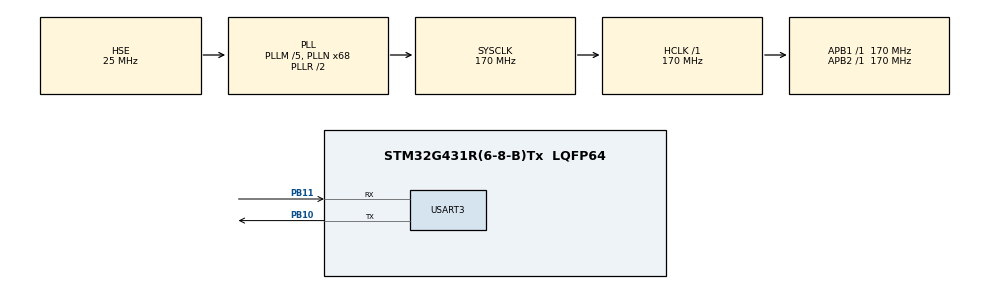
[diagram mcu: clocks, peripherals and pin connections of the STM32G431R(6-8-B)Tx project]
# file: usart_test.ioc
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Dma.Request0=USART3_TX
Dma.USART3_TX.0.Direction=DMA_MEMORY_TO_PERIPH
Dma.USART3_TX.0.EventEnable=DISABLE
Dma.USART3_TX.0.Instance=DMA1_Channel1
Dma.USART3_TX.0.MemDataAlignment=DMA_MDATAALIGN_BYTE
Dma.USART3_TX.0.MemInc=DMA_MINC_ENABLE
Dma.USART3_TX.0.Mode=DMA_CIRCULAR
Dma.USART3_TX.0.PeriphDataAlignment=DMA_PDATAALIGN_BYTE
Dma.USART3_TX.0.PeriphInc=DMA_PINC_DISABLE
Dma.USART3_TX.0.Polarity=HAL_DMAMUX_REQ_GEN_RISING
Dma.USART3_TX.0.Priority=DMA_PRIORITY_LOW
Dma.USART3_TX.0.RequestNumber=1
Dma.USART3_TX.0.SignalID=NONE
Dma.USART3_TX.0.SyncEnable=DISABLE
Dma.USART3_TX.0.SyncPolarity=HAL_DMAMUX_SYNC_NO_EVENT
Dma.USART3_TX.0.SyncRequestNumber=1
Dma.USART3_TX.0.SyncSignalID=NONE
Mcu.Family=STM32G4
Mcu.Name=STM32G431R(6-8-B)Tx
Mcu.Package=LQFP64
NVIC.DMA1_Channel1_IRQn=true\:0\:0\:false\:false\:true\:false\:true\:true
NVIC.PriorityGroup=NVIC_PRIORITYGROUP_4
PA13.Mode=Serial_Wire
PA13.Signal=SYS_JTMS-SWDIO
PA14.Mode=Serial_Wire
PA14.Signal=SYS_JTCK-SWCLK
PB10.Mode=Asynchronous
PB10.Signal=USART3_TX
PB11.Mode=Asynchronous
PB11.Signal=USART3_RX
PF0-OSC_IN.Mode=HSE-External-Oscillator
PF0-OSC_IN.Signal=RCC_OSC_IN
PF1-OSC_OUT.Mode=HSE-External-Oscillator
PF1-OSC_OUT.Signal=RCC_OSC_OUT
ProjectManager.HeapSize=0x200
ProjectManager.StackSize=0x400
ProjectManager.TargetToolchain=MDK-ARM V5.32
RCC.ADC12Freq_Value=170000000
RCC.AHBFreq_Value=170000000
RCC.APB1Freq_Value=170000000
RCC.APB1TimFreq_Value=170000000
RCC.APB2Freq_Value=170000000
RCC.APB2TimFreq_Value=170000000
RCC.CortexFreq_Value=170000000
RCC.EXTERNAL_CLOCK_VALUE=12288000
RCC.HCLKFreq_Value=170000000
RCC.HSE_VALUE=25000000
RCC.HSI48_VALUE=48000000
RCC.HSI_VALUE=16000000
RCC.LSE_VALUE=32768
RCC.PLLM=RCC_PLLM_DIV5
RCC.PLLN=68
RCC.PLLSourceVirtual=RCC_PLLSOURCE_HSE
RCC.SYSCLKFreq_VALUE=170000000
RCC.SYSCLKSource=RCC_SYSCLKSOURCE_PLLCLK
RCC.USBFreq_Value=170000000
RCC.VCOOutputFreq_Value=340000000
USART3.VirtualMode-Asynchronous=VM_ASYNC
VP_SYS_VS_DBSignals.Mode=DisableDeadBatterySignals
board=custom

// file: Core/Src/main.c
/* USER CODE BEGIN Header */
/**
  ******************************************************************************
  * @file           : main.c
  * @brief          : Main program body
  ******************************************************************************
  * @attention
  *
  * Copyright (c) 2023 STMicroelectronics.
  * All rights reserved.
  *
  * This software is licensed under terms that can be found in the LICENSE file
  * in the root directory of this software component.
  * If no LICENSE file comes with this software, it is provided AS-IS.
  *
  ******************************************************************************
  */
/* USER CODE END Header */
#include "main.h"
#include "dma.h"
#include "usart.h"
#include "gpio.h"

/* USER CODE BEGIN Includes */
#include "math.h"
/* USER CODE END Includes */

void SystemClock_Config(void);

/* USER CODE BEGIN 0 */
uint8_t data[] = "hello";

#define BYTE0(dwTemp)     (*(char*)(&dwTemp))
#define BYTE1(dwTemp)     (*((char*)(&dwTemp) + 1))
#define BYTE2(dwTemp)     (*((char*)(&dwTemp) + 2))
#define BYTE3(dwTemp)     (*((char*)(&dwTemp) + 3))

static uint8_t tempData_NM[16] = {0xAB,0xFE,0x05,0xF1,0x08,0x00,0x00,0x00,0x00,0x00,0x00,0x00,0x00,0x00,0x00,0x00};

void UART_Debug(int16_t Ia, int16_t Ib)
{
	uint16_t flen = tempData_NM[4]+tempData_NM[5]*256;
	uint8_t sumcheck=0;
	uint8_t addcheck=0;

	static uint16_t scnt = 0;
	scnt++;
	if(scnt >= 360)
		scnt = 0;

	float v1 = sin((double)scnt / 180 * 3.14159) * 180 + 180;

	tempData_NM[6] = BYTE0(Ia);
	tempData_NM[7] = BYTE1(Ia);

	tempData_NM[8] = BYTE0(Ib);
	tempData_NM[9] = BYTE1(Ib);

	tempData_NM[10] = BYTE0(v1);
	tempData_NM[11] = BYTE1(v1);
	tempData_NM[12] = BYTE2(v1);
	tempData_NM[13] = BYTE3(v1);

	for(uint16_t i=0;i<(flen+6);i++)
	{
		sumcheck+=tempData_NM[i];
		addcheck+=sumcheck;

	}
	tempData_NM[14]=(uint8_t)sumcheck;
	tempData_NM[15]=(uint8_t)addcheck;

	HAL_UART_Transmit_DMA(&huart3, (uint8_t *)tempData_NM, 16);

}
/* USER CODE END 0 */

int main(void)
{

  /* MCU Configuration--------------------------------------------------------*/

  /* Reset of all peripherals, Initializes the Flash interface and the Systick. */
  HAL_Init();

  /* USER CODE BEGIN Init */
	uint32_t time;
  /* USER CODE END Init */

  /* Configure the system clock */
  SystemClock_Config();

  /* Initialize all configured peripherals */
  MX_GPIO_Init();
  MX_DMA_Init();
  MX_USART3_UART_Init();

  /* Infinite loop */
  /* USER CODE BEGIN WHILE */
  while (1)
  {
		if (HAL_GetTick() - time > 1)
		{
//			HAL_UART_Transmit_DMA(&huart3, data, sizeof(data));
			UART_Debug(100, 200);
			time = HAL_GetTick();
		}

    /* USER CODE END WHILE */

  }
}

void SystemClock_Config(void)
{
  RCC_OscInitTypeDef RCC_OscInitStruct = {0};
  RCC_ClkInitTypeDef RCC_ClkInitStruct = {0};

  /** Configure the main internal regulator output voltage
  */
  HAL_PWREx_ControlVoltageScaling(PWR_REGULATOR_VOLTAGE_SCALE1_BOOST);

  /** Initializes the RCC Oscillators according to the specified parameters
  * in the RCC_OscInitTypeDef structure.
  */
  RCC_OscInitStruct.OscillatorType = RCC_OSCILLATORTYPE_HSE;
  RCC_OscInitStruct.HSEState = RCC_HSE_ON;
  RCC_OscInitStruct.PLL.PLLState = RCC_PLL_ON;
  RCC_OscInitStruct.PLL.PLLSource = RCC_PLLSOURCE_HSE;
  RCC_OscInitStruct.PLL.PLLM = RCC_PLLM_DIV5;
  RCC_OscInitStruct.PLL.PLLN = 68;
  RCC_OscInitStruct.PLL.PLLP = RCC_PLLP_DIV2;
  RCC_OscInitStruct.PLL.PLLQ = RCC_PLLQ_DIV2;
  RCC_OscInitStruct.PLL.PLLR = RCC_PLLR_DIV2;
  if (HAL_RCC_OscConfig(&RCC_OscInitStruct) != HAL_OK)
  {
    Error_Handler();
  }

  /** Initializes the CPU, AHB and APB buses clocks
  */
  RCC_ClkInitStruct.ClockType = RCC_CLOCKTYPE_HCLK|RCC_CLOCKTYPE_SYSCLK
                              |RCC_CLOCKTYPE_PCLK1|RCC_CLOCKTYPE_PCLK2;
  RCC_ClkInitStruct.SYSCLKSource = RCC_SYSCLKSOURCE_PLLCLK;
  RCC_ClkInitStruct.AHBCLKDivider = RCC_SYSCLK_DIV1;
  RCC_ClkInitStruct.APB1CLKDivider = RCC_HCLK_DIV1;
  RCC_ClkInitStruct.APB2CLKDivider = RCC_HCLK_DIV1;

  if (HAL_RCC_ClockConfig(&RCC_ClkInitStruct, FLASH_LATENCY_4) != HAL_OK)
  {
    Error_Handler();
  }
}

void Error_Handler(void)
{
  __disable_irq();
  while (1)
  {
  }
}
